# CC13x0 register map
File version: 2.0
CPU: CM3 r2p1, little endian, no MPU, no FPU, 0x3 interrupt priority bits, 0x0 interrupts
Registers are 32-bit, read-write, reset 0x0 unless marked. A register's access mark holds for its fields unless they carry their own. Offsets are from the block's base; [hi:lo] are bit positions.

## AUX_WUC — AUX Wake-up controller
Base 0x400C6000
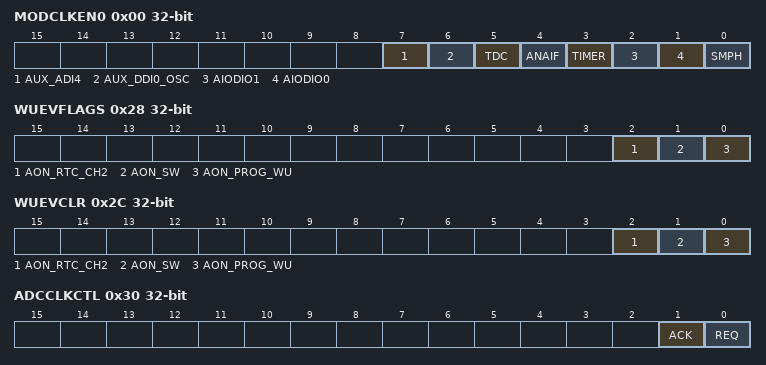
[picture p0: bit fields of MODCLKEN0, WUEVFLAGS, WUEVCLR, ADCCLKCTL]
0x00 MODCLKEN0 — Module Clock Enable Clock enable for each module in the AUX domain For use by the system CPU The settings in this register are OR'ed with the corresponding settings in MODCLKEN1. This allows the system CPU and AUX_SCE to request clocks independently. Settings take effect immediately.
  [7] AUX_ADI4, [6] AUX_DDI0_OSC, [5] TDC, [4] ANAIF, [3] TIMER, [2] AIODIO1, [1] AIODIO0, [0] SMPH
0x04 PWROFFREQ — Power Off Request Requests power off request for the AUX domain. When powered of the power supply and clock is disabled. This may only be used when taking the entire device into shutdown mode (i.e. with full device reset when resuming operation). Power off is prevented if AON_WUC:AUXCTL.AUX_FORCE_ON has been set, or if MCUBUSCTL.DISCONNECT_REQ has been cleared.
  [0] REQ
0x08 PWRDWNREQ — Power Down Request Request from AUX for system to enter power down. When system is in power down there is limited current supply available and the clock source is set by AON_WUC:AUXCLK.PWR_DWN_SRC
  [0] REQ
0x0C PWRDWNACK ro — Power Down Acknowledgment
  [0] ACK
0x10 CLKLFREQ — Low Frequency Clock Request
  [0] REQ
0x14 CLKLFACK ro — Low Frequency Clock Acknowledgment
  [0] ACK
0x28 WUEVFLAGS ro — Wake-up Event Flags Status of wake-up events from the AON domain The event flags are cleared by setting the corresponding bits in WUEVCLR
  [2] AON_RTC_CH2, [1] AON_SW, [0] AON_PROG_WU
0x2C WUEVCLR — Wake-up Event Clear Clears wake-up events from the AON domain
  [2] AON_RTC_CH2, [1] AON_SW, [0] AON_PROG_WU
0x30 ADCCLKCTL — ADC Clock Control Controls the ADC internal clock Note that the ADC command and data interface requires MODCLKEN0.ANAIF or MODCLKEN1.ANAIF also to be set
  [1] ACK, [0] REQ
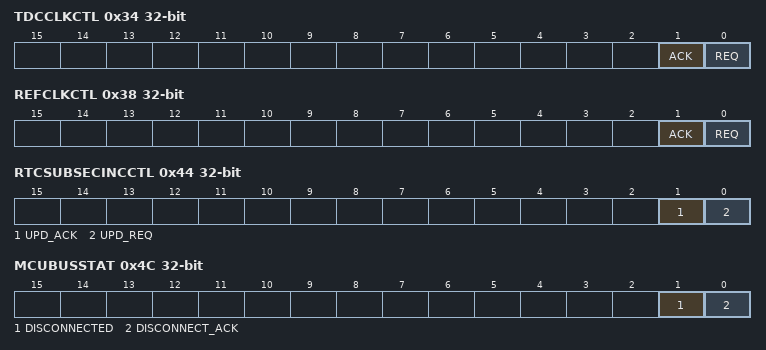
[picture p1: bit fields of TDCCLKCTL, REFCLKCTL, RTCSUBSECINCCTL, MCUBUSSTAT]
0x34 TDCCLKCTL — TDC Clock Control Controls the TDC counter clock source, which steps the TDC counter value The source of this clock is controlled by OSC_DIG:CTL0.ACLK_TDC_SRC_SEL.
  [1] ACK, [0] REQ
0x38 REFCLKCTL — Reference Clock Control Controls the TDC reference clock source, which is to be compared against the TDC counter clock. The source of this clock is controlled by OSC_DIG:CTL0.ACLK_REF_SRC_SEL.
  [1] ACK, [0] REQ
0x3C RTCSUBSECINC0 — Real Time Counter Sub Second Increment 0 New value for the real-time counter (AON_RTC) sub-second increment value, part corresponding to AON_RTC:SUBSECINC bits 15:0. After setting INC15_0 and RTCSUBSECINC1.INC23_16, the value is loaded into AON_RTC:SUBSECINC.VALUEINC by setting RTCSUBSECINCCTL.UPD_REQ.
  [15:0] INC15_0
0x40 RTCSUBSECINC1 — Real Time Counter Sub Second Increment 1 New value for the real-time counter (AON_RTC) sub-second increment value, part corresponding to AON_RTC:SUBSECINC bits 23:16. After setting RTCSUBSECINC0.INC15_0 and INC23_16, the value is loaded into AON_RTC:SUBSECINC.VALUEINC by setting RTCSUBSECINCCTL.UPD_REQ.
  [7:0] INC23_16
0x44 RTCSUBSECINCCTL — Real Time Counter Sub Second Increment Control
  [1] UPD_ACK, [0] UPD_REQ
0x48 MCUBUSCTL — MCU Bus Control Controls the connection between the AUX domain bus and the MCU domain bus. The buses must be disconnected to allow power-down or power-off of the AUX domain.
  [0] DISCONNECT_REQ
0x4C MCUBUSSTAT ro — MCU Bus Status Indicates the connection state of the AUX domain and MCU domain buses. Note that this register cannot be read from the MCU domain while disconnected, and is therefore only useful for the AUX_SCE.
  [1] DISCONNECTED, [0] DISCONNECT_ACK
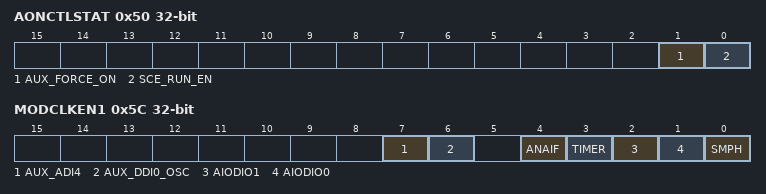
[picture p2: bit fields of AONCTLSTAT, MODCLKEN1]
0x50 AONCTLSTAT ro — AON Domain Control Status Status of AUX domain control from AON_WUC.
  [1] AUX_FORCE_ON, [0] SCE_RUN_EN
0x54 AUXIOLATCH — AUX Input Output Latch Controls latching of signals between AUX_AIODIO0/AUX_AIODIO1 and AON_IOC.
  [0] EN
0x5C MODCLKEN1 — Module Clock Enable 1 Clock enable for each module in the AUX domain, for use by the AUX_SCE. Settings take effect immediately. The settings in this register are OR'ed with the corresponding settings in MODCLKEN0. This allows system CPU and AUX_SCE to request clocks independently.
  [7] AUX_ADI4, [6] AUX_DDI0_OSC, [4] ANAIF, [3] TIMER, [2] AIODIO1, [1] AIODIO0, [0] SMPH
